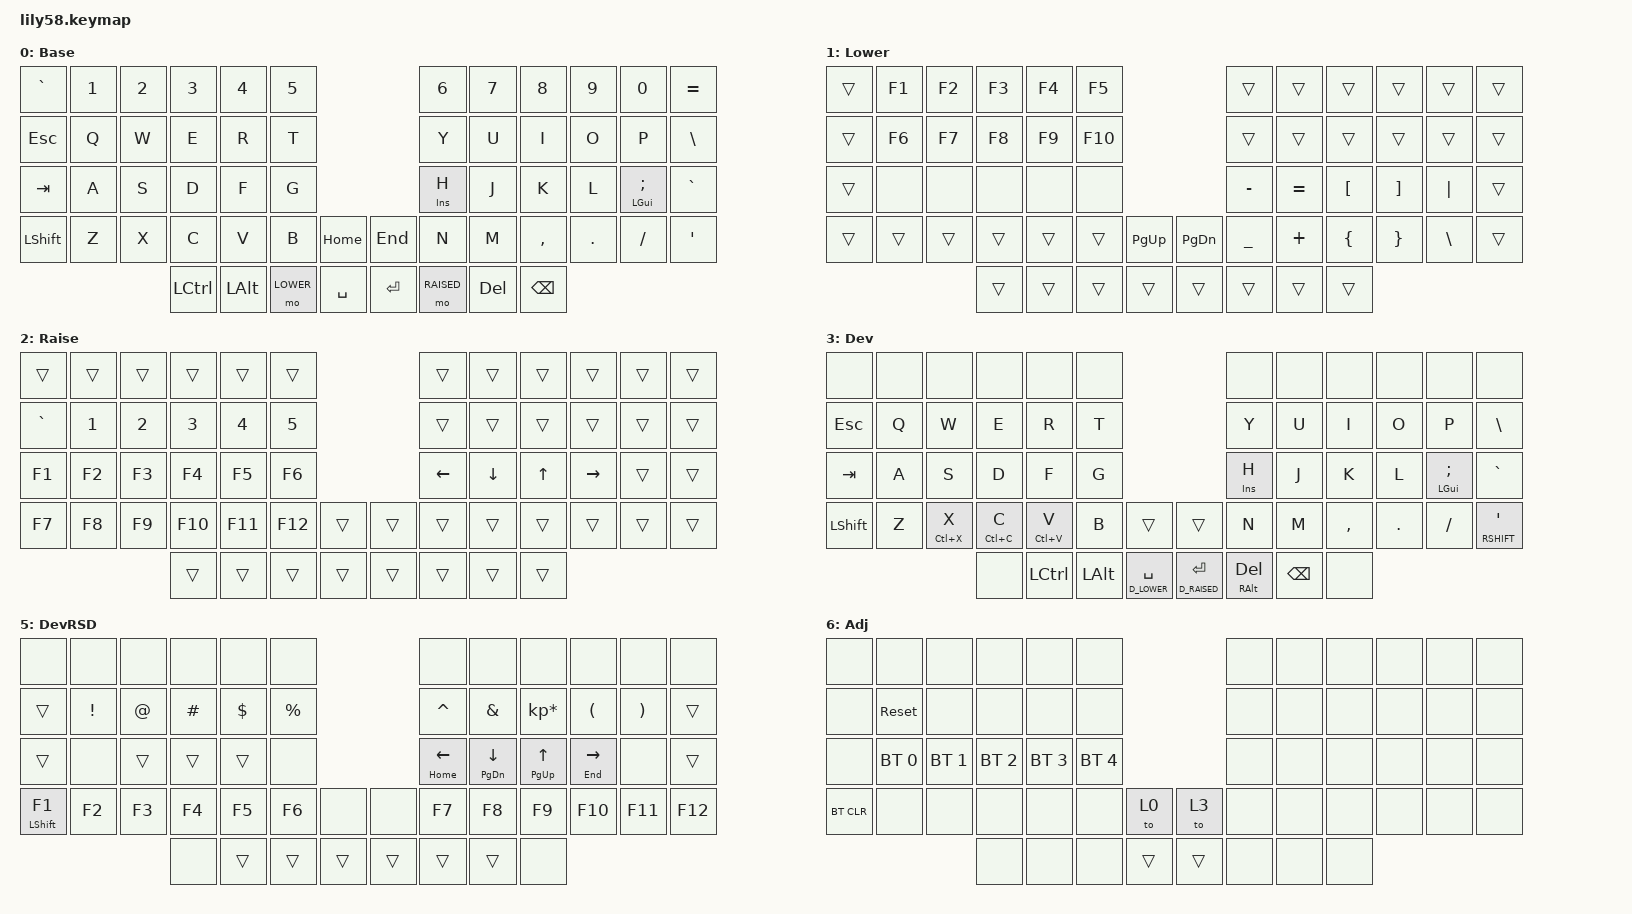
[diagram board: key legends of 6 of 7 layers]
/*
 * Copyright (c) 2020 The ZMK Contributors
 *
 * SPDX-License-Identifier: MIT
 */

#include <behaviors.dtsi>
#include <dt-bindings/zmk/keys.h>
#include <dt-bindings/zmk/bt.h>
#include <dt-bindings/zmk/pointing.h>
#include <dt-bindings/zmk/ext_power.h>
#include "config.h"
#define ADJUST 6
#define D_LOWER 4
#define D_RAISED 5
#include "my-behaviours.dtsi"

/ {
    conditional_layers {
        compatible = "zmk,conditional-layers";
        tri_layer_dev {
            if-layers = <D_LOWER D_RAISED>;
            then-layer = <ADJUST>;
        };
    };

    keymap {
        compatible = "zmk,keymap";

        default_layer {
            display-name = "Base";
            bindings = <
&kp GRAVE &kp N1 &kp N2 &kp N3   &kp N4   &kp N5                         &kp N6       &kp N7      &kp N8       &kp N9       &kp N0     &kp EQUAL
&kp ESC   &kp Q  &kp W  &kp E    &kp R    &kp T                          &kp Y        &kp U       &kp I        &kp O        &kp P      &kp BSLH
&kp TAB   &kp A  &kp S  &kp D    &kp F    &kp G                          &ht INSERT H &kp J       &kp K        &kp L        &ht LGUI SEMI &kp GRAVE   
&kp LSHFT &kp Z  &kp X  &kp C    &kp V    &kp B      &kp HOME   &kp END  &kp N        &kp M       &kp COMMA    &kp DOT      &kp FSLH   &kp SQT
                       &kp LCTRL &kp LALT &mo LOWER  &kp SPACE  &kp RET  &mo RAISED   &kp DEL     &kp BSPC
            >;

            sensor-bindings = <&inc_dec_kp C_VOL_UP C_VOL_DN>;
        };

        lower_layer {
            display-name = "Lower";
            bindings = <
&trans     &kp F1           &kp F2            &kp F3            &kp F4       &kp F5                       &trans    &trans    &trans          &trans    &trans    &trans
&trans     &kp F6           &kp F7            &kp F8            &kp F9       &kp F10                      &trans    &trans    &trans          &trans    &trans    &trans
&trans     &none            &none             &none             &none        &none                        &kp MINUS &kp EQUAL &kp LBKT        &kp RBKT  &kp PIPE  &trans
&trans     &trans           &trans            &trans            &trans       &trans  &kp PG_UP &kp PG_DN  &kp UNDER &kp PLUS  &kp LBRC        &kp RBRC  &kp BSLH  &trans
                                              &trans            &trans       &trans  &trans    &trans     &trans    &trans    &trans
            >;

            sensor-bindings = <&inc_dec_kp C_VOL_UP C_VOL_DN>;
        };

        raise_layer {
            display-name = "Raise";
            bindings = <
&trans    &trans &trans &trans  &trans  &trans                       &trans      &trans    &trans    &trans    &trans    &trans
&kp GRAVE &kp N1 &kp N2 &kp N3  &kp N4  &kp N5                       &trans      &trans    &trans    &trans    &trans    &trans
&kp F1    &kp F2 &kp F3 &kp F4  &kp F5  &kp F6                       &kp LEFT    &kp DOWN  &kp UP    &kp RIGHT &trans    &trans
&kp F7    &kp F8 &kp F9 &kp F10 &kp F11 &kp F12   &trans   &trans    &trans      &trans    &trans    &trans    &trans    &trans
                        &trans  &trans  &trans    &trans   &trans    &trans      &trans    &trans
            >;

            sensor-bindings = <&inc_dec_kp C_VOL_UP C_VOL_DN>;
        };

       default_dev_layer {
                       display-name = "Dev";
                        bindings = <
     &none          &none        &none          &none       &none           &none                                             &none        &none        &none        &none      &none         &none
     &kp ESC        &kp Q        &kp W          &kp E       &kp R           &kp T                                             &kp Y        &kp U        &kp I        &kp O      &kp P         &kp BSLH
     &kp TAB        &kp A        &kp S          &kp D       &kp F           &kp G                                             &ht INSERT H &kp J        &kp K        &kp L      &ht LGUI SEMI &kp GRAVE   
     &kp LSHFT      &kp Z        &ht LC(X) X    &ht LC(C) C &ht LC(V) V     &kp B          &trans            &trans           &kp N        &kp M      &kp COMMA    &kp DOT      &kp FSLH      &lt RSHIFT SQT
                                                &none       &kp LCTRL       &kp LALT       &lt D_LOWER SPACE &lt D_RAISED RET &mt RALT DEL &kp BSPC   &none
                        >;
                };
             lower_dev_layer {
                       display-name = "DevLOW";
                        bindings = <
     &none          &none        &none          &none          &none           &none                                        &none             &none             &none              &none            &none      &none
     &trans         AS(N1)       AS(N2)         AS(N3)         AS(N4)          AS(N5)                                       AS(N6)            AS(N7)            AS(N8)             AS(N9)           AS(N0)     &trans 
     &trans         &mkp LCLK    &mkp RCLK      &msc SCRL_UP   &kp LSHIFT      &none                                        &kp MINUS         &kp EQUAL         &kp LBKT           &kp RBKT         &kp PIPE   &trans
     &trans         &none        &none          &msc SCRL_DOWN &none           &none          &none             &none       &kp UNDER         &kp PLUS          &kp LBRC           &kp RBRC         &kp BSLH   &kp TILDE
                                                &none          &trans          &trans         &trans            &trans      &trans            &trans
                        >;
            };

            raise_dev_layer {
                        display-name = "DevRSD";
                        bindings = <
      &none           &none        &none          &none       &none           &none                                &none             &none             &none           &none         &none       &none 
      &trans          &kp EXCL     &kp AT         &kp HASH    &kp DLLR        &kp PRCNT                            &kp CARET         &kp AMPS          &kp KP_MULTIPLY &kp LPAR      &kp RPAR    &trans
      &trans          &none        &trans         &trans      &trans          &none                                &ht HOME LEFT     &ht PG_DN DOWN    &ht PG_UP UP    &ht END RIGHT &none       &trans
      &ht LSHFT F1    &kp F2       &kp F3         &kp F4      &kp F5          &kp F6     &none          &none      &kp F7            &kp F8            &kp F9          &kp F10       &kp F11     &kp F12
                                                  &none       &trans          &trans     &trans         &trans     &trans            &trans            &none
                        >;
            };
            adjust_layer {
                       display-name = "Adj";
                        bindings = <
   &none         &none        &none        &none        &none        &none                                  &none        &none      &none        &none        &none    &none
   &none         &sys_reset   &none        &none        &none        &none                                  &none        &none      &none        &none        &none    &none
   &none         &bt BT_SEL 0 &bt BT_SEL 1 &bt BT_SEL 2 &bt BT_SEL 3 &bt BT_SEL 4                           &none        &none      &none        &none        &none    &none
   &bt BT_CLR    &none        &none        &none        &none        &none        &to 0          &to 3      &none        &none      &none        &none        &none    &none 
                                           &none        &none        &none        &trans         &trans     &none        &none      &none
                        >;                  
                };
 
    };
};
 
